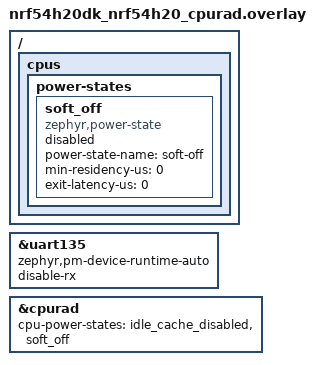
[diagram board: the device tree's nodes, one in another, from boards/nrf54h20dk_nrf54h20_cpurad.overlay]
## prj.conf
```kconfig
CONFIG_PM=y
CONFIG_PM_DEVICE=y
CONFIG_PM_DEVICE_RUNTIME=y
CONFIG_POWEROFF=y
CONFIG_UART_ASYNC_API=y
CONFIG_SERIAL=y
CONFIG_CONSOLE=y
CONFIG_UART_CONSOLE=y
```

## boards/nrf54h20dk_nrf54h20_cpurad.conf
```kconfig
CONFIG_LOG=n
CONFIG_SERIAL=n
CONFIG_UART_CONSOLE=n
CONFIG_CONSOLE=n
CONFIG_PRINTK=n
CONFIG_EARLY_CONSOLE=n
CONFIG_NCS_BOOT_BANNER=n
CONFIG_ASSERT_VERBOSE=n
CONFIG_BOOT_BANNER=n
```

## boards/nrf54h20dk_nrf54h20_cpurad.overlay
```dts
&uart135 {
	status = "okay";
	zephyr,pm-device-runtime-auto;
	disable-rx;
};

/ {
	cpus {
		power-states {
			soft_off: soft_off {
			compatible = "zephyr,power-state";
			power-state-name = "soft-off";
			min-residency-us = <0>;
			exit-latency-us = <0>;
			status = "disabled";
			};
		};
	};
};

&cpurad {
	cpu-power-states = <&idle_cache_disabled &soft_off>;
};
```

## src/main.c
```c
/* Copyright (c) 2024 Nordic Semiconductor ASA
 *
 * SPDX-License-Identifier: Apache-2.0
 */

#include <zephyr/kernel.h>
#include <zephyr/device.h>
#include <zephyr/pm/device.h>
#include <zephyr/pm/device_runtime.h>
#include <zephyr/pm/pm.h>
#include <zephyr/sys/poweroff.h>
#include <zephyr/drivers/timer/nrf_grtc_timer.h>

int main(void)
{

	if (IS_ENABLED(CONFIG_CONSOLE)) {
		printf("%s system off demo. Ready for system off.\n", CONFIG_BOARD_QUALIFIERS);
	}

	if (IS_ENABLED(CONFIG_PM_DEVICE) && IS_ENABLED(CONFIG_SERIAL)) {
		static const struct device *cons = DEVICE_DT_GET(DT_CHOSEN(zephyr_console));
		int err;
		enum pm_device_state state;

		if (cons) {
			do {
				err = pm_device_state_get(cons, &state);
			} while ((err == 0) && (state == PM_DEVICE_STATE_ACTIVE));
		}
	}

	pm_state_force(0u, &(struct pm_state_info){PM_STATE_SOFT_OFF, 0, 0});
	k_sleep(K_FOREVER);

	return 0;
}
```
